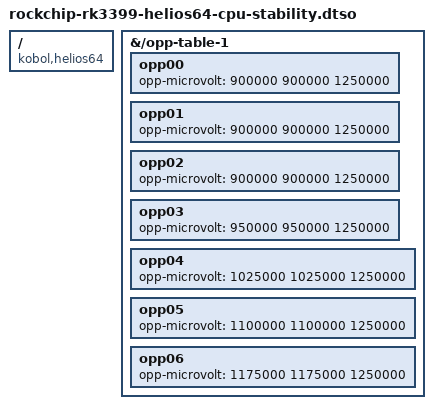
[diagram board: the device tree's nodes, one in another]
// SPDX-License-Identifier: GPL-2.0
/dts-v1/;
/plugin/;

/ {
    compatible = "kobol,helios64";

    fragment@0 {
        target-path = "/opp-table-1";
        __overlay__ {
            /* opp-microvolt raised by +75 mV vs mainline (op1-opp.dtsi). */
            /*  408 MHz: 0.825 V -> 0.900 V */
            opp00 { opp-microvolt = < 900000  900000 1250000>; };
            /*  600 MHz: 0.825 V -> 0.900 V */
            opp01 { opp-microvolt = < 900000  900000 1250000>; };
            /*  816 MHz: 0.825 V -> 0.900 V */
            opp02 { opp-microvolt = < 900000  900000 1250000>; };
            /* 1008 MHz: 0.875 V -> 0.950 V */
            opp03 { opp-microvolt = < 950000  950000 1250000>; };
            /* 1200 MHz: 0.950 V -> 1.025 V */
            opp04 { opp-microvolt = <1025000 1025000 1250000>; };
            /* 1416 MHz: 1.025 V -> 1.100 V */
            opp05 { opp-microvolt = <1100000 1100000 1250000>; };
            /* 1608 MHz: 1.100 V -> 1.175 V */
            opp06 { opp-microvolt = <1175000 1175000 1250000>; };
            /* 1800 MHz: 1.200 V — unchanged from mainline */
        };
    };
};
